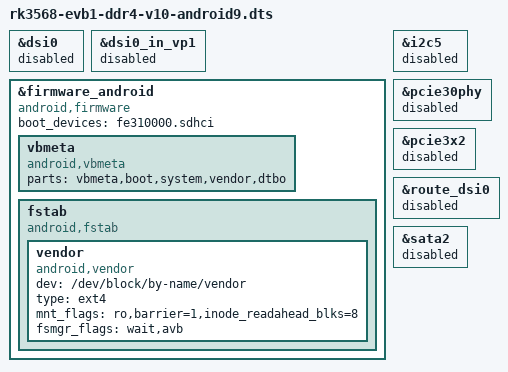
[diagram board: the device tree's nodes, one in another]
// SPDX-License-Identifier: (GPL-2.0+ OR MIT)
/*
 * Copyright (c) 2020 Rockchip Electronics Co., Ltd.
 *
 */

#include "rk3568-evb1-ddr4-v10.dtsi"
#include "rk3568-android9.dtsi"

&dsi0 {
	status = "disabled";
};

&dsi0_in_vp1 {
	status = "disabled";
};

&firmware_android {
	compatible = "android,firmware";
	boot_devices = "fe310000.sdhci";
	vbmeta {
		compatible = "android,vbmeta";
		parts = "vbmeta,boot,system,vendor,dtbo";
	};
	fstab {
		compatible = "android,fstab";
		vendor {
			compatible = "android,vendor";
			dev = "/dev/block/by-name/vendor";
			type = "ext4";
			mnt_flags = "ro,barrier=1,inode_readahead_blks=8";
			fsmgr_flags = "wait,avb";
		};
	};
};

&i2c5 {
	status = "disabled";
};

&pcie30phy {
	status = "disabled";
};

&pcie3x2 {
	status = "disabled";
};

&route_dsi0 {
	status = "disabled";
};

&sata2 {
	status = "disabled";
};
